# SF32LB57x register map
File version: 1.0
CPU: CM33 r0p1, little endian, MPU, FPU, 3 interrupt priority bits
Registers are 32-bit, read-write, reset 0x0 unless marked. A register's access mark holds for its fields unless they carry their own. Offsets are from the block's base; [hi:lo] are bit positions; {n}, {i} and the like mark numbered series.

## PMUC
Base 0x500CA000
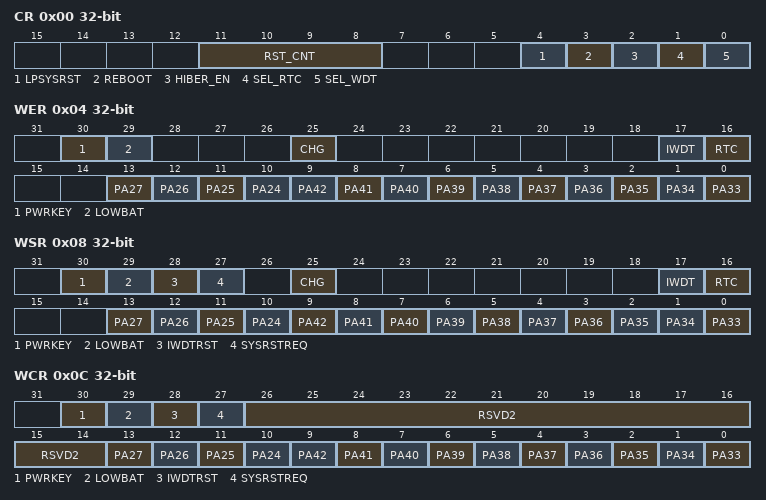
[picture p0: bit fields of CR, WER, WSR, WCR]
0x00 CR — Control Register
  [11:8] RST_CNT — Determine the reset pulse width for both LPSYSRST and SYSRSTREQ
  [4] LPSYSRST — Write 1 to resetn LPSYS, self-cleared when reset done
  [3] REBOOT — Write 1 to reboot; write 0 to clear after boot up
  [2] HIBER_EN — Write 1 to enter hibernate mode; write 0 to clear when exit from hibernate
  [1] SEL_RTC — Clock select for RTC. 0: LRC10, 1: LXT32
  [0] SEL_WDT — Clock select for WDT and PMUC FSM. 0: LRC10, 1: LRC32
0x04 WER — Wakeup Enable register
  [30] PWRKEY — Enable PWRKEY to restart the whole chip
  [29] LOWBAT — Enable LOWBAT to restart the whole chip
  [25] CHG — Enable Charger event as wakeup source. See charger control register for details.
  [17] IWDT — Enable IWDT 1st round timeout as wakeup source
  [16] RTC — Enable RTC as wakeup source
  [n-14] PA{n} (n=24..27)
  [n-33] PA{n} (n=34..42)
  [0] PA33 — Enable PA33 as wakeup source
0x08 WSR — Wakeup Status register
  [30] PWRKEY — Indicates reset by PWRKEY
  [29] LOWBAT — Indicates reset by LOWBAT
  [28] IWDTRST — Indicates reset by IWDT 2nd round timeout
  [27] SYSRSTREQ — Indicates reset by HCPU sysresetreq
  [25] CHG — Indicates wakeup by charger event
  [17] IWDT — Indicates wakeup by IWDT 1st round timeout
  [16] RTC — Indicates wakeup by RTC
  [n-14] PA{n} (n=24..27)
  [n-33] PA{n} (n=35..42)
  [1] PA34 — Indicates wakeup by PA34
  [0] PA33 — Indicates wakeup by PA33
0x0C WCR — Wakeup Clear register
  [30] PWRKEY — Write 1 to clear PWRKEY reset flag
  [29] LOWBAT — Write 1 to clear LOWBAT flag
  [28] IWDTRST — Write 1 to clear IWDT reset flag
  [27] SYSRSTREQ — Write 1 to clear SYSRSTREQ reset flag
  [26:14] RSVD2 — Clear the status in RTC/IWDT/CHG
  [n-14] PA{n} (n=24..27)
  [n-33] PA{n} (n=34..42)
  [0] PA33 — Write 1 to clear PA33 wakeup flag. Only valid if PIN wakeup is configured as edge trigger
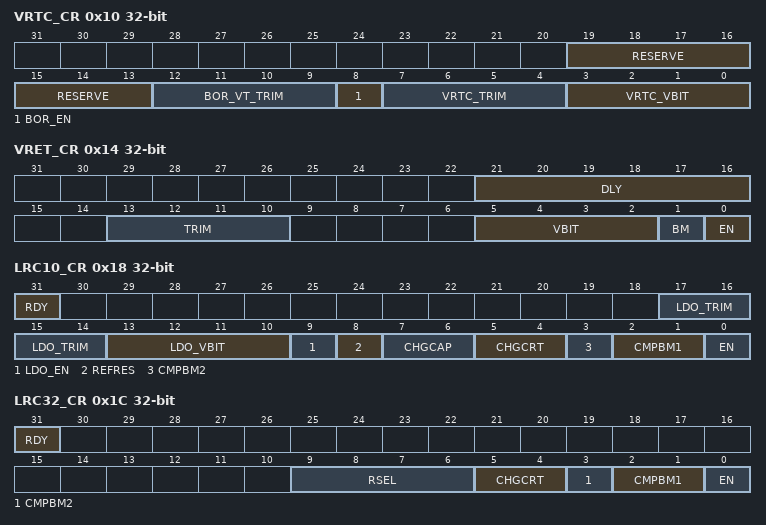
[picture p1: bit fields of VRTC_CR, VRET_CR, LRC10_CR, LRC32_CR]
0x10 VRTC_CR — VRTC Control Register
  [19:13] RESERVE
  [12:9] BOR_VT_TRIM
  [8] BOR_EN — Brownout Reset Enable
  [7:4] VRTC_TRIM
  [3:0] VRTC_VBIT
0x14 VRET_CR — VRET Control Register
  [21:16] DLY — VRET_LDO power up delay in number of CLK_LP cycles
  [13:10] TRIM
  [5:2] VBIT
  [1] BM
  [0] EN
0x18 LRC10_CR — RC10K Control Register
  [31] RDY
  [17:14] LDO_TRIM
  [13:10] LDO_VBIT
  [9] LDO_EN
  [8] REFRES
  [7:6] CHGCAP
  [5:4] CHGCRT
  [3] CMPBM2
  [2:1] CMPBM1
  [0] EN — Enabled by default
0x1C LRC32_CR — RC32K Control Register
  [31] RDY
  [9:6] RSEL
  [5:4] CHGCRT
  [3] CMPBM2
  [2:1] CMPBM1
  [0] EN — Disabled by default
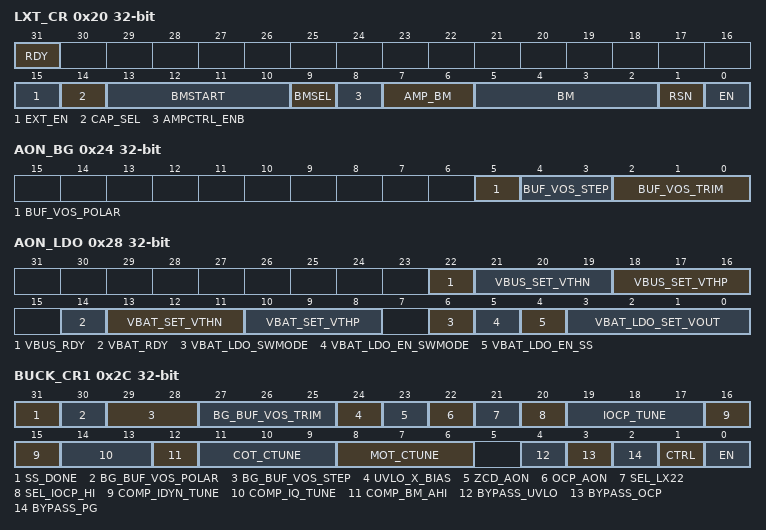
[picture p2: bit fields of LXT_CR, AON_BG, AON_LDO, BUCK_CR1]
0x20 LXT_CR — XTAL32K Control Register
  [31] RDY
  [15] EXT_EN — use external 32K from Pin
  [14] CAP_SEL
  [13:10] BMSTART
  [9] BMSEL
  [8] AMPCTRL_ENB
  [7:6] AMP_BM
  [5:2] BM
  [1] RSN
  [0] EN
0x24 AON_BG — AON Bandgap Register
  [5] BUF_VOS_POLAR, [4:3] BUF_VOS_STEP, [2:0] BUF_VOS_TRIM
0x28 AON_LDO
  [22] VBUS_RDY, [21:19] VBUS_SET_VTHN, [18:16] VBUS_SET_VTHP, [14] VBAT_RDY, [13:11] VBAT_SET_VTHN, [10:8] VBAT_SET_VTHP, [6] VBAT_LDO_SWMODE, [5] VBAT_LDO_EN_SWMODE, [4] VBAT_LDO_EN_SS, [3:0] VBAT_LDO_SET_VOUT
0x2C BUCK_CR1 — BUCK Control Register 1
  [31] SS_DONE, [30] BG_BUF_VOS_POLAR, [29:28] BG_BUF_VOS_STEP, [27:25] BG_BUF_VOS_TRIM, [24] UVLO_X_BIAS, [23] ZCD_AON, [22] OCP_AON, [21] SEL_LX22, [20] SEL_IOCP_HI, [19:17] IOCP_TUNE, [16:15] COMP_IDYN_TUNE, [14:13] COMP_IQ_TUNE, [12] COMP_BM_AHI, [11:9] COT_CTUNE, [8:6] MOT_CTUNE, [4] BYPASS_UVLO, [3] BYPASS_OCP, [2] BYPASS_PG, [1] CTRL, [0] EN
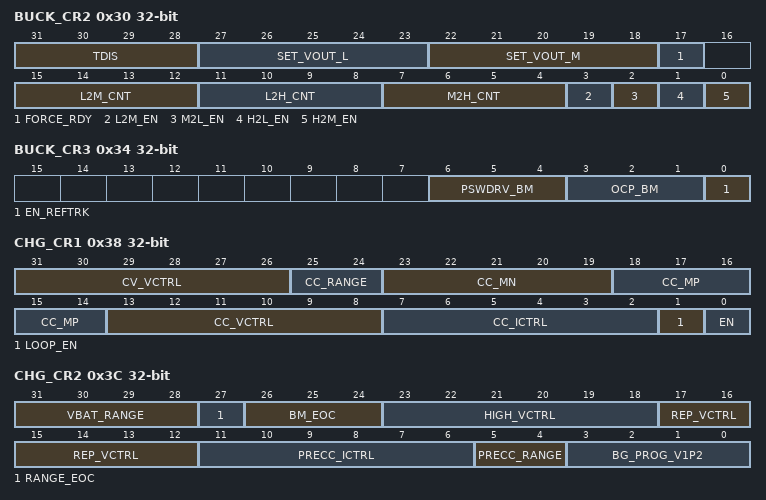
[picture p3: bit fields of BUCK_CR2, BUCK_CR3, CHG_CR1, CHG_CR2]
0x30 BUCK_CR2 — BUCK Control Register 2
  [31:28] TDIS — Discharge for TDIS*4 LP clock cycles during reboot
  [27:23] SET_VOUT_L — 0.75V
  [22:18] SET_VOUT_M — 1.1V
  [17] FORCE_RDY
  [15:12] L2M_CNT
  [11:8] L2H_CNT
  [7:4] M2H_CNT
  [3] L2M_EN
  [2] M2L_EN
  [1] H2L_EN
  [0] H2M_EN
0x34 BUCK_CR3 — BUCK Control Register 3
  [6:4] PSWDRV_BM, [3:1] OCP_BM, [0] EN_REFTRK
0x38 CHG_CR1 — Charger Control Register 1
  [31:26] CV_VCTRL
  [25:24] CC_RANGE
  [23:19] CC_MN
  [18:14] CC_MP
  [13:8] CC_VCTRL
  [7:2] CC_ICTRL
  [1] LOOP_EN — only available when CR3 FORCE_CTRL bit is set
  [0] EN — only available when CR3 FORCE_CTRL bit is set
0x3C CHG_CR2 — Charger Control Register 2
  [31:28] VBAT_RANGE, [27] RANGE_EOC, [26:24] BM_EOC, [23:18] HIGH_VCTRL, [17:12] REP_VCTRL, [11:6] PRECC_ICTRL, [5:4] PRECC_RANGE, [3:0] BG_PROG_V1P2
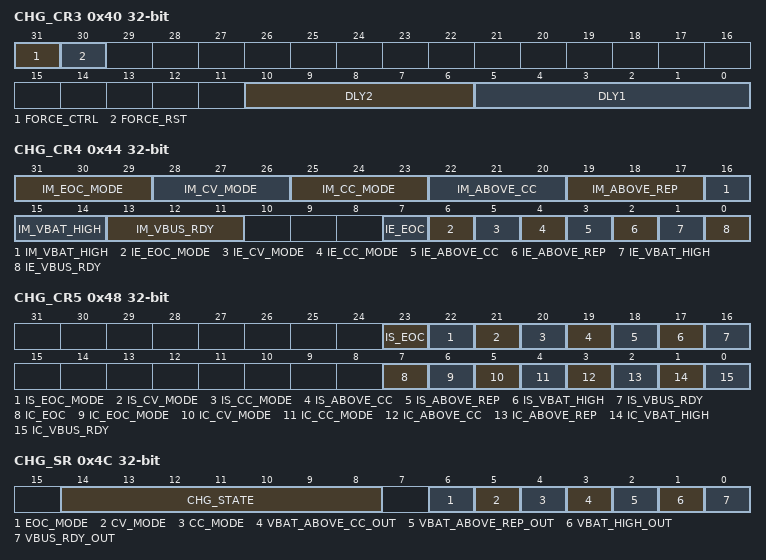
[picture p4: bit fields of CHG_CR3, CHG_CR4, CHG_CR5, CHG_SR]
0x40 CHG_CR3 — Charger Control Register 3
  [31] FORCE_CTRL — When charger plugged out, this bit will auto reset
  [30] FORCE_RST — When charger plugged out, this bit will auto reset
  [10:6] DLY2
  [5:0] DLY1
0x44 CHG_CR4 — Charger Control Register 4
  [31:29] IM_EOC_MODE
  [28:26] IM_CV_MODE
  [25:23] IM_CC_MODE
  [22:20] IM_ABOVE_CC
  [19:17] IM_ABOVE_REP
  [16:14] IM_VBAT_HIGH
  [13:11] IM_VBUS_RDY — 0: high level, 1: low level, 2: pos edge, 3: neg edge, others: both edge
  [7] IE_EOC
  [6] IE_EOC_MODE
  [5] IE_CV_MODE
  [4] IE_CC_MODE
  [3] IE_ABOVE_CC
  [2] IE_ABOVE_REP
  [1] IE_VBAT_HIGH
  [0] IE_VBUS_RDY
0x48 CHG_CR5 — Charger Control Register 5
  [23] IS_EOC, [22] IS_EOC_MODE, [21] IS_CV_MODE, [20] IS_CC_MODE, [19] IS_ABOVE_CC, [18] IS_ABOVE_REP, [17] IS_VBAT_HIGH, [16] IS_VBUS_RDY, [7] IC_EOC, [6] IC_EOC_MODE, [5] IC_CV_MODE, [4] IC_CC_MODE, [3] IC_ABOVE_CC, [2] IC_ABOVE_REP, [1] IC_VBAT_HIGH, [0] IC_VBUS_RDY
0x4C CHG_SR — Charger Status Register
  [14:8] CHG_STATE — Charger finite state machine
  [6] EOC_MODE
  [5] CV_MODE
  [4] CC_MODE
  [3] VBAT_ABOVE_CC_OUT
  [2] VBAT_ABOVE_REP_OUT
  [1] VBAT_HIGH_OUT
  [0] VBUS_RDY_OUT
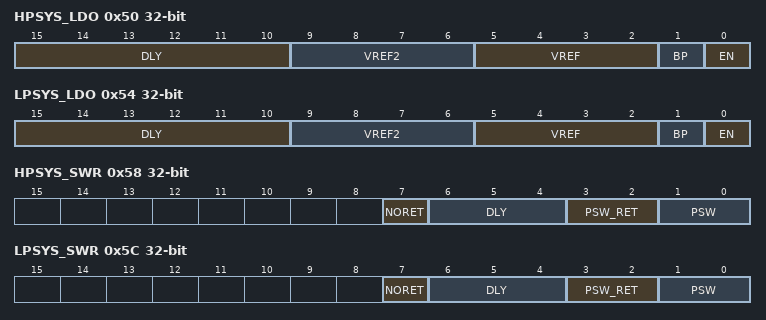
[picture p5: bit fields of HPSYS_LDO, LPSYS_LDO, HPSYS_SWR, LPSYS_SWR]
0x50 HPSYS_LDO — HPSYS LDO Control Register
  [15:10] DLY — HPSYS_LDO power up delay in CLK_LP cycles
  [9:6] VREF2 — Lower voltage for deep sleep mode (0.6V)
  [5:2] VREF — optional voltage (0.9V)
  [1] BP
  [0] EN
0x54 LPSYS_LDO — LPSYS LDO Control Register
  [15:10] DLY — LPSYS_LDO power up delay in CLK_LP cycles
  [9:6] VREF2 — Lower voltage for deep sleep mode (0.6V)
  [5:2] VREF — optional voltage (1.0V)
  [1] BP
  [0] EN
0x58 HPSYS_SWR — HPSYS Switch Register
  [7] NORET — Cut off VHPMEM entirely during standby. No retention
  [6:4] DLY — wait for N cycles before asserting RDY
  [3:2] PSW_RET — PSW value during DS/SB
  [1:0] PSW — [0]: RET_LDO; [1]: HPSYS_LDO
0x5C LPSYS_SWR — LPSYS Switch Register
  [7] NORET — Cut off VLPMEM entirely during standby. No retention
  [6:4] DLY — wait for N cycles before asserting RDY
  [3:2] PSW_RET — PSW value during DS/SB
  [1:0] PSW — [0]: RET_LDO; [1]: LPSYS_LDO
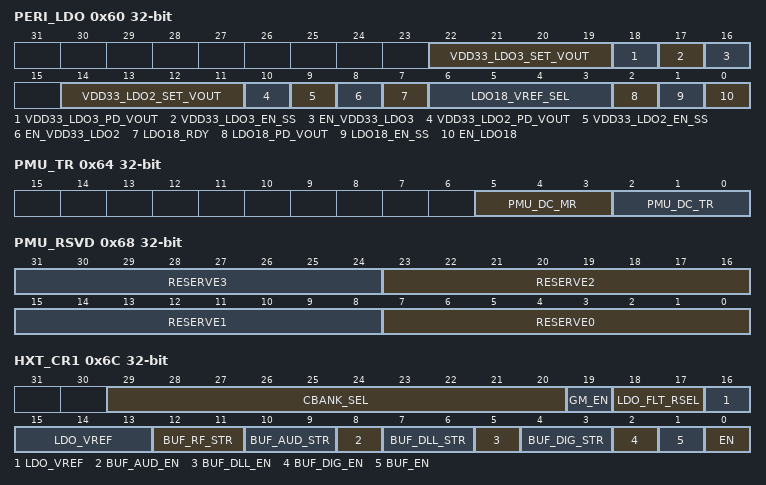
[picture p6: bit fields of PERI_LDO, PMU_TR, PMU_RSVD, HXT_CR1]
0x60 PERI_LDO — Peripherals LDO
  [22:19] VDD33_LDO3_SET_VOUT, [18] VDD33_LDO3_PD_VOUT, [17] VDD33_LDO3_EN_SS, [16] EN_VDD33_LDO3, [14:11] VDD33_LDO2_SET_VOUT, [10] VDD33_LDO2_PD_VOUT, [9] VDD33_LDO2_EN_SS, [8] EN_VDD33_LDO2, [7] LDO18_RDY, [6:3] LDO18_VREF_SEL, [2] LDO18_PD_VOUT, [1] LDO18_EN_SS, [0] EN_LDO18
0x64 PMU_TR — PMU Test Register
  [5:3] PMU_DC_MR — macro select
  [2:0] PMU_DC_TR — test point select
0x68 PMU_RSVD — PMU Reserved Register
  [8n+7:8n] RESERVE{n} (n=0..3)
0x6C HXT_CR1 — HXT48 Control Register 1
  [29:20] CBANK_SEL, [19] GM_EN, [18:17] LDO_FLT_RSEL, [16:13] LDO_VREF, [12:11] BUF_RF_STR, [10:9] BUF_AUD_STR, [8] BUF_AUD_EN, [7:6] BUF_DLL_STR, [5] BUF_DLL_EN, [4:3] BUF_DIG_STR, [2] BUF_DIG_EN, [1] BUF_EN, [0] EN
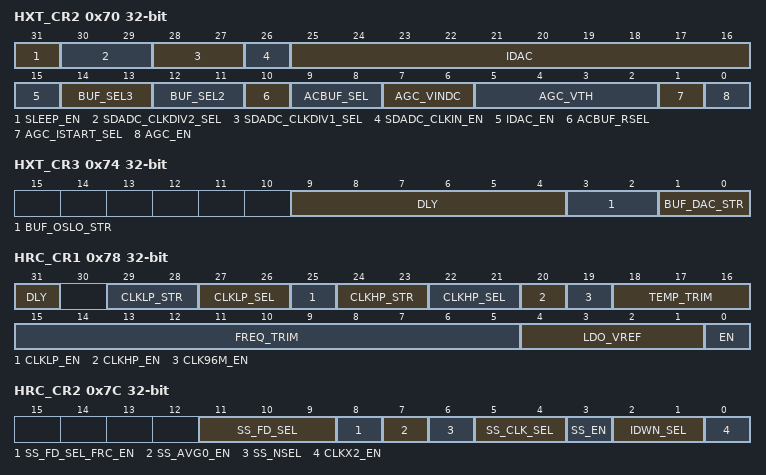
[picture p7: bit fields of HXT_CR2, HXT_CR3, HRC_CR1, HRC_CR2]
0x70 HXT_CR2 — HXT48 Control Register 2
  [31] SLEEP_EN, [30:29] SDADC_CLKDIV2_SEL, [28:27] SDADC_CLKDIV1_SEL, [26] SDADC_CLKIN_EN, [25:16] IDAC, [15] IDAC_EN, [14:13] BUF_SEL3, [12:11] BUF_SEL2, [10] ACBUF_RSEL, [9:8] ACBUF_SEL, [7:6] AGC_VINDC, [5:2] AGC_VTH, [1] AGC_ISTART_SEL, [0] AGC_EN
0x74 HXT_CR3 — HXT48 Control Register 3
  [9:4] DLY, [3:2] BUF_OSLO_STR, [1:0] BUF_DAC_STR
0x78 HRC_CR1 — HRC48 Control Register 1
  [31] DLY — number of cycles for BG ready. 0: one cycle of CLK_LP; 1: two cycles of CLK_LP
  [29:28] CLKLP_STR
  [27:26] CLKLP_SEL
  [25] CLKLP_EN
  [24:23] CLKHP_STR
  [22:21] CLKHP_SEL
  [20] CLKHP_EN
  [19] CLK96M_EN
  [18:16] TEMP_TRIM
  [15:5] FREQ_TRIM
  [4:1] LDO_VREF
  [0] EN
0x7C HRC_CR2 — HRC48 Control Register 2
  [11:9] SS_FD_SEL, [8] SS_FD_SEL_FRC_EN, [7] SS_AVG0_EN, [6] SS_NSEL, [5:4] SS_CLK_SEL, [3] SS_EN, [2:1] IDWN_SEL, [0] CLKX2_EN
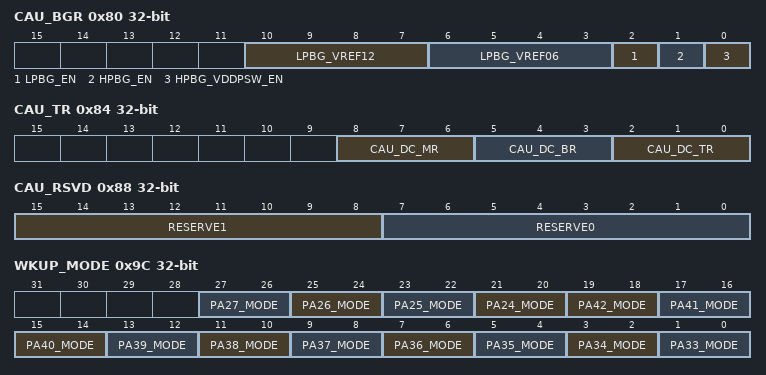
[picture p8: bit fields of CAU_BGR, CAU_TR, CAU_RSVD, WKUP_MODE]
0x80 CAU_BGR — CAU Bandgap Register
  [10:7] LPBG_VREF12, [6:3] LPBG_VREF06, [2] LPBG_EN, [1] HPBG_EN, [0] HPBG_VDDPSW_EN
0x84 CAU_TR — CAU Test Register
  [8:6] CAU_DC_MR, [5:3] CAU_DC_BR, [2:0] CAU_DC_TR
0x88 CAU_RSVD — CAU Reserved Register
  [15:8] RESERVE1, [7:0] RESERVE0
0x8C PWRKEY_CNT — PowerKey Count Register
  [19:4] RST_CNT — press high for RST_CNT*16 CLK_WDT cycles to reset the whole chip
0x90 HPSYS_VOUT
  [3:0] VOUT — 0xD: 1.2V, 0xA: 1.1V, 0x8: 1.0V, 0x5: 0.9V
0x94 LPSYS_VOUT
  [3:0] VOUT — 0x8: 1.0V, 0x5: 0.9V
0x98 BUCK_VOUT
  [4:0] VOUT — 0xF: 1.35V, 0xD: 1.25V, 0x9: 1.05V, 0x6: 0.9V, 0x2: 0.7V
0x9C WKUP_MODE — Wakeup Mode Register
  [2n-27:2n-28] PA{n}_MODE (n=24..27)
  [2n-65:2n-66] PA{n}_MODE (n=34..42)
  [1:0] PA33_MODE — 0: high level, 1: low level, 2: pos edge, 3: neg edge
0xA0 WKUP_CNT — Wakeup Count Register
  [15:0] PIN_DLY — De-glitch for PIN_DLY cycles of CLK_LP
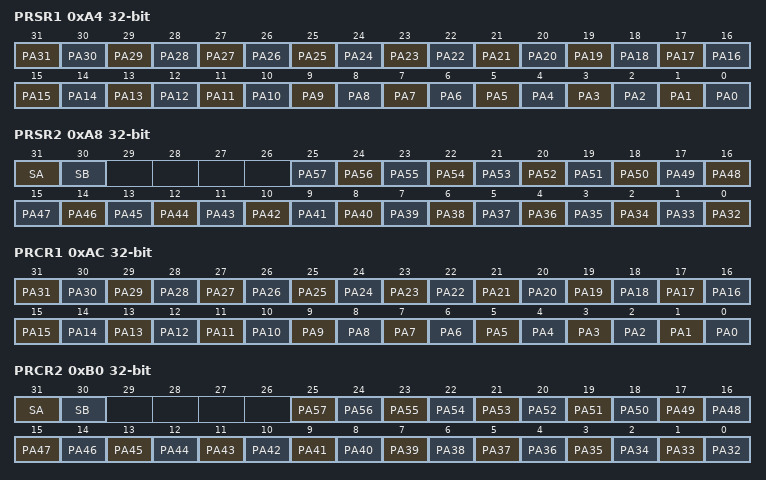
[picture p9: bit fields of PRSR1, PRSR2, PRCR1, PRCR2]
0xA4 PRSR1 — PAD Retention Set Register 1
  [n] PA{n} (n=1..31)
  [0] PA0 — Write 1 to set PA0 retention
0xA8 PRSR2 — PAD Retention Set Register 2
  [31] SA, [30] SB, [n-32] PA{n} (n=32..57)
0xAC PRCR1 — PAD Retention Clear Register 1
  [n] PA{n} (n=1..31)
  [0] PA0 — Write 1 to clear PA0 retention
0xB0 PRCR2 — PAD Retention Clear Register 2
  [31] SA
  [30] SB
  [n-32] PA{n} (n=33..57)
  [0] PA32 — Write 1 to clear PA32 retention
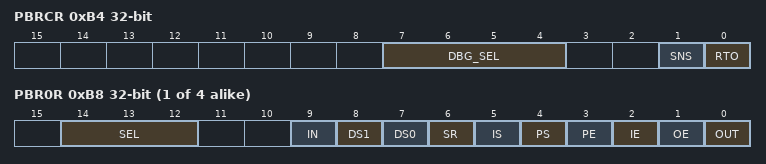
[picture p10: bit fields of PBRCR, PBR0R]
0xB4 PBRCR — PBR Control Register
  [7:4] DBG_SEL, [1] SNS, [0] RTO
{0xB8+4i} PBR{i}R (i=0..3) — PBR{i} Register
  [14:12] SEL, [9] IN, [8] DS1, [7] DS0, [6] SR, [5] IS, [4] PS, [3] PE, [2] IE, [1] OE, [0] OUT
0xC8 PAWK1R — PA Wakeup Register 1
  [9:0] PE
0xCC PAWK2R — PA Wakeup Register 2
  [9:0] PS
0xD0 PAWK3R — PA Wakeup Register 3
  [9:0] IS
